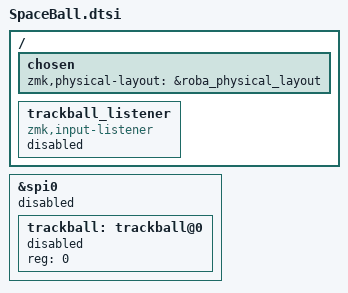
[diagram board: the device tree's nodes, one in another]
#include <dt-bindings/zmk/matrix_transform.h>
#include <physical_layouts.dtsi>

/ {
    chosen {
        zmk,physical-layout = &roba_physical_layout;
    };

    trackball_listener: trackball_listener {
        compatible = "zmk,input-listener";
        status = "disabled";
    };
};

&spi0 {
    status = "disabled";

    trackball: trackball@0 {
        status = "disabled";
        reg = <0>;
    };
};
